# PIC32MK0512MCF100 register map
Vendor: Microchip
Registers are 32-bit, read-write, reset 0x0 unless marked. A register's access mark holds for its fields unless they carry their own. Addresses are absolute, and some are shared; only a register's first bit layout is shown; [hi:lo] are bit positions; {n}, {i} and the like mark numbered series.

## UART6
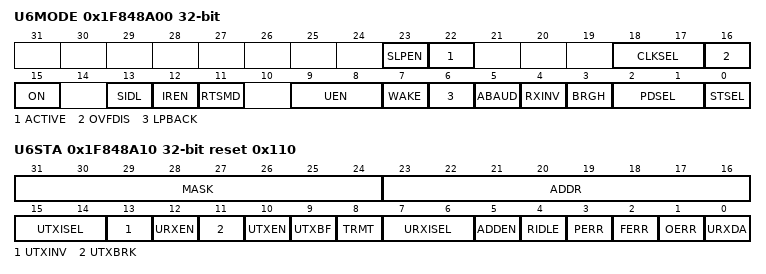
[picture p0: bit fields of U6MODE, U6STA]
0x1F848A00 U6MODE
  [23] SLPEN, [22] ACTIVE, [18:17] CLKSEL, [16] OVFDIS, [15] ON, [13] SIDL, [12] IREN, [11] RTSMD, [9:8] UEN, [7] WAKE, [6] LPBACK, [5] ABAUD, [4] RXINV, [3] BRGH, [2:1] PDSEL, [0] STSEL
0x1F848A10 U6STA reset 0x110
  [31:24] MASK
  [23:16] ADDR
  [15:14] UTXISEL
  [13] UTXINV
  [12] URXEN
  [11] UTXBRK
  [10] UTXEN
  [9] UTXBF ro
  [8] TRMT ro
  [7:6] URXISEL
  [5] ADDEN
  [4] RIDLE ro
  [3] PERR ro
  [2] FERR ro
  [1] OERR — (can only be cleared)
  [0] URXDA ro
0x1F848A20 U6TXREG
  [8:0] U6TXREG
0x1F848A30 U6RXREG ro
  [8:0] U6RXREG
0x1F848A40 U6BRG
  [19:0] BRG

## CDAC2
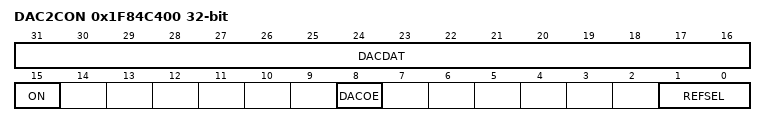
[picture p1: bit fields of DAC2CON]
0x1F84C400 DAC2CON — CDAC Control Register
  [31:16] DACDAT — Data Input Register Bits for the CDAC
  [15] ON — CDAC Enable
    0=The CDAC is Disabled; 1=The CDAC is Enabled
  [8] DACOE — CDAC Output Enable
    0=Output is Disabled; drive to pin is floating; 1=Output is Enabled; CDAC voltage is connected to the pin
  [1:0] REFSEL — Reference Source Select
    0=No Reference Selected (no current consumed); 1=Positive Reference Voltage = External Vref+ Pin; 2=Positive Reference Voltage = 2 * Internal Bandgap Reference Voltage; 3=Positive Reference Voltage = AVdd

## CDAC3
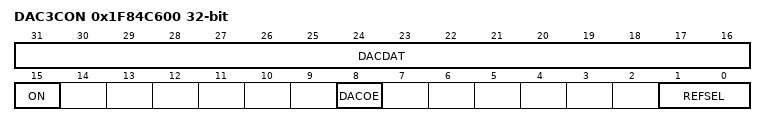
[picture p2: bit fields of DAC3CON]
0x1F84C600 DAC3CON — CDAC Control Register
  [31:16] DACDAT — Data Input Register Bits for the CDAC
  [15] ON — CDAC Enable
    0=The CDAC is Disabled; 1=The CDAC is Enabled
  [8] DACOE — CDAC Output Enable
    0=Output is Disabled; drive to pin is floating; 1=Output is Enabled; CDAC voltage is connected to the pin
  [1:0] REFSEL — Reference Source Select
    0=No Reference Selected (no current consumed); 1=Positive Reference Voltage = External Vref+ Pin; 2=Positive Reference Voltage = 2 * Internal Bandgap Reference Voltage; 3=Positive Reference Voltage = AVdd

## gpio_ports_upb
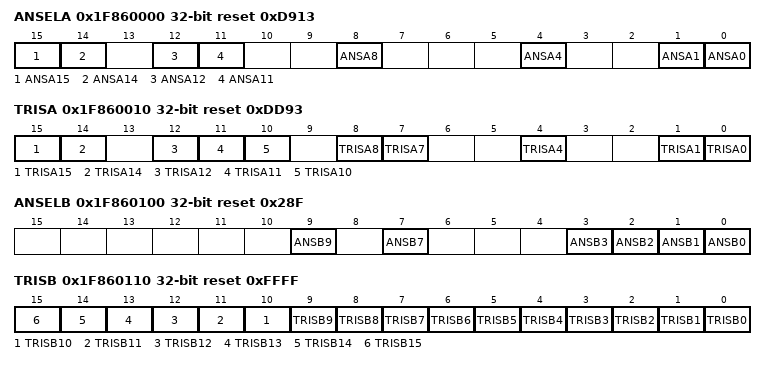
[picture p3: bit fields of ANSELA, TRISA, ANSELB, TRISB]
0x1F860000 ANSELA reset 0xD913
  [15] ANSA15, [14] ANSA14, [12] ANSA12, [11] ANSA11, [8] ANSA8, [4] ANSA4, [1] ANSA1, [0] ANSA0
0x1F860010 TRISA reset 0xDD93
  [15] TRISA15, [14] TRISA14, [12] TRISA12, [11] TRISA11, [10] TRISA10, [8] TRISA8, [7] TRISA7, [4] TRISA4, [1] TRISA1, [0] TRISA0
0x1F860100 ANSELB reset 0x28F
  [9] ANSB9, [7] ANSB7, [n] ANSB{n} (n=0..3)
0x1F860110 TRISB reset 0xFFFF
  [n] TRISB{n} (n=0..15)
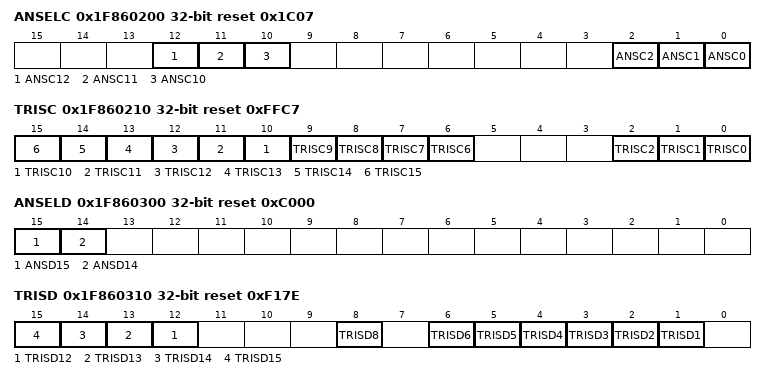
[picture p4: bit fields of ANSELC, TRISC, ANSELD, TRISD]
0x1F860200 ANSELC reset 0x1C07
  [12] ANSC12, [11] ANSC11, [10] ANSC10, [2] ANSC2, [1] ANSC1, [0] ANSC0
0x1F860210 TRISC reset 0xFFC7
  [n] TRISC{n} (n=6..15), [2] TRISC2, [1] TRISC1, [0] TRISC0
0x1F860300 ANSELD reset 0xC000
  [15] ANSD15, [14] ANSD14
0x1F860310 TRISD reset 0xF17E
  [n] TRISD{n} (n=12..15), [8] TRISD8, [n] TRISD{n} (n=1..6)
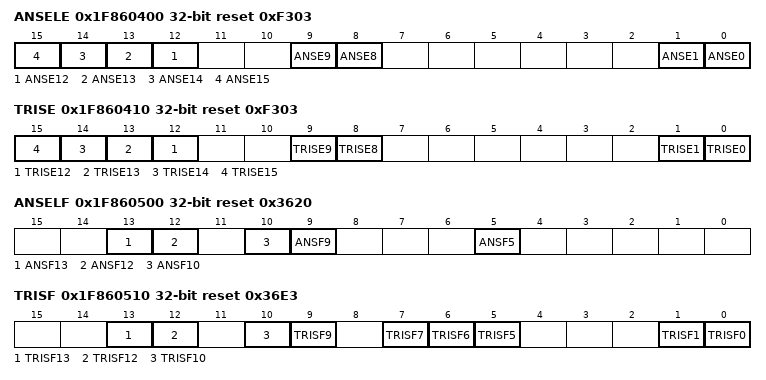
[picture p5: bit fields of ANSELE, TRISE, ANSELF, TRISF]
0x1F860400 ANSELE reset 0xF303
  [n] ANSE{n} (n=12..15), [9] ANSE9, [8] ANSE8, [1] ANSE1, [0] ANSE0
0x1F860410 TRISE reset 0xF303
  [n] TRISE{n} (n=12..15), [9] TRISE9, [8] TRISE8, [1] TRISE1, [0] TRISE0
0x1F860500 ANSELF reset 0x3620
  [13] ANSF13, [12] ANSF12, [10] ANSF10, [9] ANSF9, [5] ANSF5
0x1F860510 TRISF reset 0x36E3
  [13] TRISF13, [12] TRISF12, [10] TRISF10, [9] TRISF9, [7] TRISF7, [6] TRISF6, [5] TRISF5, [1] TRISF1, [0] TRISF0
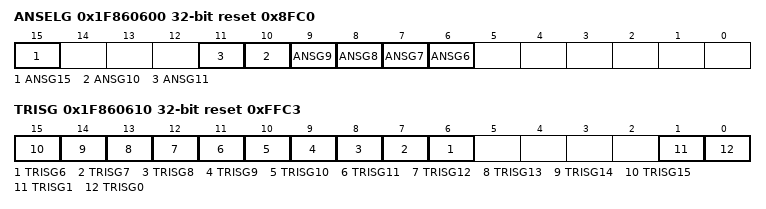
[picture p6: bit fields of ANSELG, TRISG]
0x1F860600 ANSELG reset 0x8FC0
  [15] ANSG15, [n] ANSG{n} (n=6..11)
0x1F860610 TRISG reset 0xFFC3
  [n] TRISG{n} (n=6..15), [1] TRISG1, [0] TRISG0

## PORTA
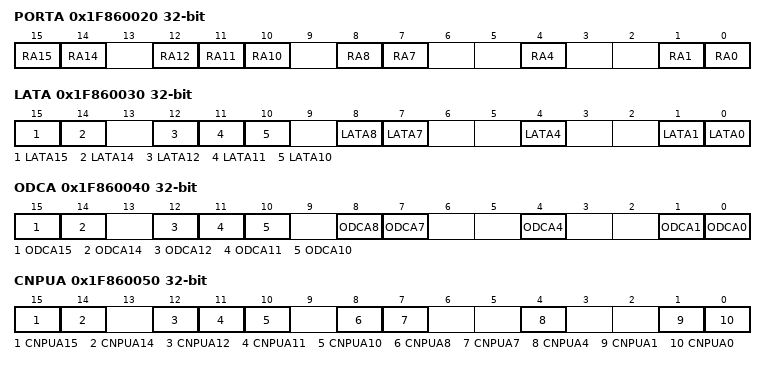
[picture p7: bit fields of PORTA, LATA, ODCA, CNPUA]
0x1F860020 PORTA reset not defined — (power-on value ----------------xx-xxx-xx--x--xx)
  [15] RA15, [14] RA14, [12] RA12, [11] RA11, [10] RA10, [8] RA8, [7] RA7, [4] RA4, [1] RA1, [0] RA0
0x1F860030 LATA reset not defined — (power-on value ----------------xx-xxx-xx--x--xx)
  [15] LATA15, [14] LATA14, [12] LATA12, [11] LATA11, [10] LATA10, [8] LATA8, [7] LATA7, [4] LATA4, [1] LATA1, [0] LATA0
0x1F860040 ODCA
  [15] ODCA15, [14] ODCA14, [12] ODCA12, [11] ODCA11, [10] ODCA10, [8] ODCA8, [7] ODCA7, [4] ODCA4, [1] ODCA1, [0] ODCA0
0x1F860050 CNPUA
  [15] CNPUA15, [14] CNPUA14, [12] CNPUA12, [11] CNPUA11, [10] CNPUA10, [8] CNPUA8, [7] CNPUA7, [4] CNPUA4, [1] CNPUA1, [0] CNPUA0
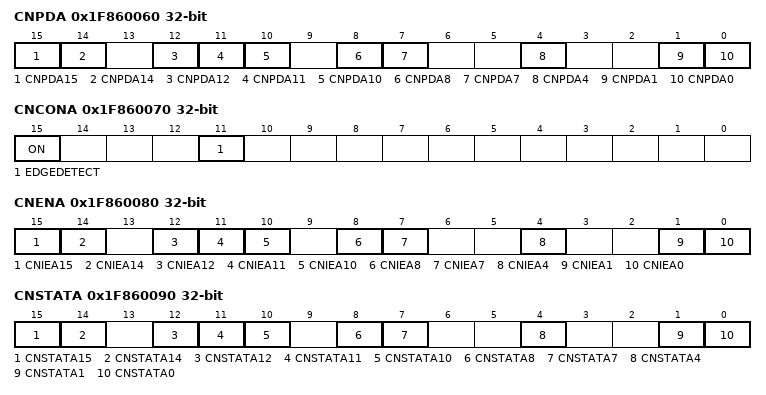
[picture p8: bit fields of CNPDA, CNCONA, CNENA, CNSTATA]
0x1F860060 CNPDA
  [15] CNPDA15, [14] CNPDA14, [12] CNPDA12, [11] CNPDA11, [10] CNPDA10, [8] CNPDA8, [7] CNPDA7, [4] CNPDA4, [1] CNPDA1, [0] CNPDA0
0x1F860070 CNCONA
  [15] ON, [11] EDGEDETECT
0x1F860080 CNENA
  [15] CNIEA15, [14] CNIEA14, [12] CNIEA12, [11] CNIEA11, [10] CNIEA10, [8] CNIEA8, [7] CNIEA7, [4] CNIEA4, [1] CNIEA1, [0] CNIEA0
0x1F860090 CNSTATA
  [15] CNSTATA15, [14] CNSTATA14, [12] CNSTATA12, [11] CNSTATA11, [10] CNSTATA10, [8] CNSTATA8, [7] CNSTATA7, [4] CNSTATA4, [1] CNSTATA1, [0] CNSTATA0
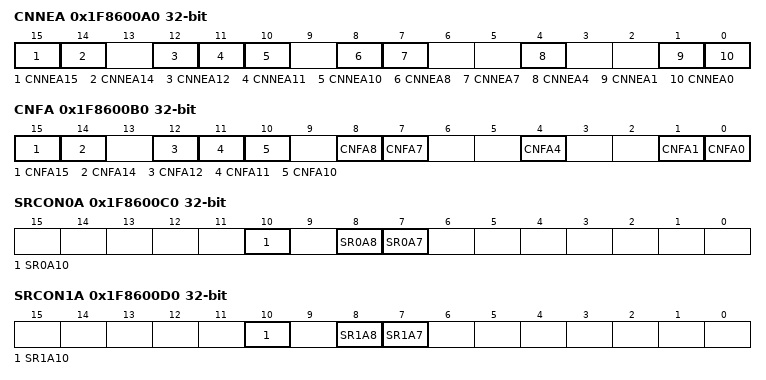
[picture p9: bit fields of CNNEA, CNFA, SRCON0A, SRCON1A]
0x1F8600A0 CNNEA
  [15] CNNEA15, [14] CNNEA14, [12] CNNEA12, [11] CNNEA11, [10] CNNEA10, [8] CNNEA8, [7] CNNEA7, [4] CNNEA4, [1] CNNEA1, [0] CNNEA0
0x1F8600B0 CNFA
  [15] CNFA15, [14] CNFA14, [12] CNFA12, [11] CNFA11, [10] CNFA10, [8] CNFA8, [7] CNFA7, [4] CNFA4, [1] CNFA1, [0] CNFA0
0x1F8600C0 SRCON0A
  [10] SR0A10, [8] SR0A8, [7] SR0A7
0x1F8600D0 SRCON1A
  [10] SR1A10, [8] SR1A8, [7] SR1A7
